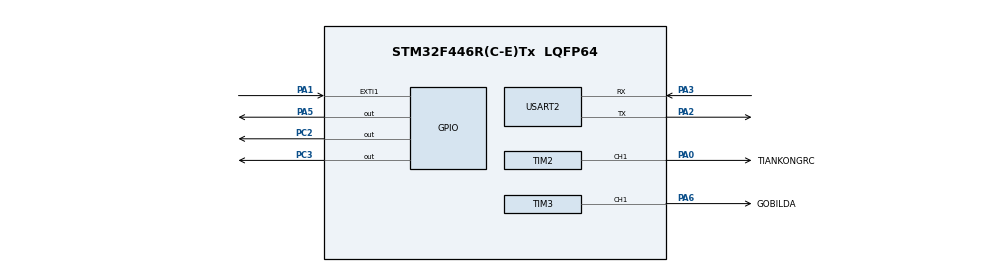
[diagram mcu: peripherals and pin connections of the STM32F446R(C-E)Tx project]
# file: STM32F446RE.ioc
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Dma.Request0=USART2_RX
Dma.Request1=USART2_TX
Dma.USART2_RX.0.Direction=DMA_PERIPH_TO_MEMORY
Dma.USART2_RX.0.FIFOMode=DMA_FIFOMODE_DISABLE
Dma.USART2_RX.0.Instance=DMA1_Stream5
Dma.USART2_RX.0.MemDataAlignment=DMA_MDATAALIGN_BYTE
Dma.USART2_RX.0.MemInc=DMA_MINC_ENABLE
Dma.USART2_RX.0.Mode=DMA_CIRCULAR
Dma.USART2_RX.0.PeriphDataAlignment=DMA_PDATAALIGN_BYTE
Dma.USART2_RX.0.PeriphInc=DMA_PINC_DISABLE
Dma.USART2_RX.0.Priority=DMA_PRIORITY_VERY_HIGH
Dma.USART2_TX.1.Direction=DMA_MEMORY_TO_PERIPH
Dma.USART2_TX.1.FIFOMode=DMA_FIFOMODE_DISABLE
Dma.USART2_TX.1.Instance=DMA1_Stream6
Dma.USART2_TX.1.MemDataAlignment=DMA_MDATAALIGN_BYTE
Dma.USART2_TX.1.MemInc=DMA_MINC_ENABLE
Dma.USART2_TX.1.Mode=DMA_NORMAL
Dma.USART2_TX.1.PeriphDataAlignment=DMA_PDATAALIGN_BYTE
Dma.USART2_TX.1.PeriphInc=DMA_PINC_DISABLE
Dma.USART2_TX.1.Priority=DMA_PRIORITY_VERY_HIGH
FREERTOS.Tasks01=defaultTask,24,5000,StartDefaultTask,As weak,NULL,Static,defaultTaskBuffer,defaultTaskControlBlock;myTask02,8,2000,StartServoTask,As weak,NULL,Static,myTask02Buffer,myTask02ControlBlock
FREERTOS.configUSE_NEWLIB_REENTRANT=1
Mcu.Family=STM32F4
Mcu.Name=STM32F446R(C-E)Tx
Mcu.Package=LQFP64
NVIC.DMA1_Stream5_IRQn=true\:5\:0\:false\:false\:true\:true\:false\:true\:true
NVIC.DMA1_Stream6_IRQn=true\:5\:0\:false\:false\:true\:true\:false\:true\:true
NVIC.EXTI1_IRQn=true\:5\:0\:false\:false\:true\:true\:true\:true\:true
NVIC.PriorityGroup=NVIC_PRIORITYGROUP_4
NVIC.TIM5_IRQn=true\:5\:0\:false\:false\:true\:true\:true\:true\:true
NVIC.TIM6_DAC_IRQn=true\:15\:0\:false\:false\:true\:false\:false\:true\:true
NVIC.TimeBase=TIM6_DAC_IRQn
NVIC.TimeBaseIP=TIM6
NVIC.USART2_IRQn=true\:5\:0\:false\:false\:true\:true\:true\:true\:true
PA0-WKUP.GPIO_Label=TIANKONGRC
PA0-WKUP.Signal=S_TIM2_CH1_ETR
PA1.GPIO_ModeDefaultEXTI=GPIO_MODE_IT_RISING_FALLING
PA1.GPIO_PuPd=GPIO_PULLUP
PA1.Signal=GPXTI1
PA13.Mode=Serial_Wire
PA13.Signal=SYS_JTMS-SWDIO
PA14.Mode=Serial_Wire
PA14.Signal=SYS_JTCK-SWCLK
PA2.Mode=Asynchronous
PA2.Signal=USART2_TX
PA3.Mode=Asynchronous
PA3.Signal=USART2_RX
PA5.Signal=GPIO_Output
PA6.GPIO_Label=GOBILDA
PA6.Signal=S_TIM3_CH1
PC2.Signal=GPIO_Output
PC3.Signal=GPIO_Output
ProjectManager.HeapSize=0x200
ProjectManager.StackSize=0x400
ProjectManager.TargetToolchain=STM32CubeIDE
RCC.CortexFreq_Value=16000000
RCC.USBFreq_Value=96000000
RCC.VCOOutputFreq_Value=192000000
SH.S_TIM2_CH1_ETR.0=TIM2_CH1,PWM Generation1 CH1
SH.S_TIM3_CH1.0=TIM3_CH1,PWM Generation1 CH1
TIM2.Channel-PWM\ Generation1\ CH1=TIM_CHANNEL_1
TIM3.Channel-PWM\ Generation1\ CH1=TIM_CHANNEL_1
TIM5.Period=10000-1
TIM5.Prescaler=16-1
USART2.VirtualMode=VM_ASYNC
VP_FREERTOS_VS_CMSIS_V2.Mode=CMSIS_V2
VP_SYS_VS_tim6.Mode=TIM6
VP_TIM5_VS_ClockSourceINT.Mode=Internal
board=custom

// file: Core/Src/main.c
/* USER CODE BEGIN Header */
/**
  ******************************************************************************
  * @file           : main.c
  * @brief          : Main program body
  ******************************************************************************
  * @attention
  *
  * Copyright (c) 2026 STMicroelectronics.
  * All rights reserved.
  *
  * This software is licensed under terms that can be found in the LICENSE file
  * in the root directory of this software component.
  * If no LICENSE file comes with this software, it is provided AS-IS.
  *
  ******************************************************************************
  */
/* USER CODE END Header */
#include "main.h"
#include "cmsis_os.h"

typedef StaticTask_t osStaticThreadDef_t;

TIM_HandleTypeDef htim2;
TIM_HandleTypeDef htim3;
TIM_HandleTypeDef htim5;

UART_HandleTypeDef huart2;
DMA_HandleTypeDef hdma_usart2_rx;
DMA_HandleTypeDef hdma_usart2_tx;

/* Definitions for defaultTask */
osThreadId_t defaultTaskHandle;
uint32_t defaultTaskBuffer[ 5000 ];
osStaticThreadDef_t defaultTaskControlBlock;
const osThreadAttr_t defaultTask_attributes = {
  .name = "defaultTask",
  .cb_mem = &defaultTaskControlBlock,
  .cb_size = sizeof(defaultTaskControlBlock),
  .stack_mem = &defaultTaskBuffer[0],
  .stack_size = sizeof(defaultTaskBuffer),
  .priority = (osPriority_t) osPriorityNormal,
};
/* Definitions for myTask02 */
osThreadId_t myTask02Handle;
uint32_t myTask02Buffer[ 2000 ];
osStaticThreadDef_t myTask02ControlBlock;
const osThreadAttr_t myTask02_attributes = {
  .name = "myTask02",
  .cb_mem = &myTask02ControlBlock,
  .cb_size = sizeof(myTask02ControlBlock),
  .stack_mem = &myTask02Buffer[0],
  .stack_size = sizeof(myTask02Buffer),
  .priority = (osPriority_t) osPriorityLow,
};
/* USER CODE BEGIN PV */
int sec =0;
/* USER CODE END PV */

void SystemClock_Config(void);
static void MX_GPIO_Init(void);
static void MX_DMA_Init(void);
static void MX_USART2_UART_Init(void);
static void MX_TIM5_Init(void);
static void MX_TIM2_Init(void);
static void MX_TIM3_Init(void);
void StartDefaultTask(void *argument);
void StartServoTask(void *argument);

int main(void)
{

  /* MCU Configuration--------------------------------------------------------*/

  /* Reset of all peripherals, Initializes the Flash interface and the Systick. */
  HAL_Init();

  /* Configure the system clock */
  SystemClock_Config();

  /* Initialize all configured peripherals */
  MX_GPIO_Init();
  MX_DMA_Init();
  MX_USART2_UART_Init();
  MX_TIM5_Init();
  MX_TIM2_Init();
  MX_TIM3_Init();

  /* Init scheduler */
  osKernelInitialize();

  /* Create the thread(s) */
  /* creation of defaultTask */
  defaultTaskHandle = osThreadNew(StartDefaultTask, NULL, &defaultTask_attributes);

  /* creation of myTask02 */
  myTask02Handle = osThreadNew(StartServoTask, NULL, &myTask02_attributes);

  /* Start scheduler */
  osKernelStart();

  /* We should never get here as control is now taken by the scheduler */

  /* Infinite loop */
  while (1)
  {

  }
}

void SystemClock_Config(void)
{
  RCC_OscInitTypeDef RCC_OscInitStruct = {0};
  RCC_ClkInitTypeDef RCC_ClkInitStruct = {0};

  /** Configure the main internal regulator output voltage
  */
  __HAL_RCC_PWR_CLK_ENABLE();
  __HAL_PWR_VOLTAGESCALING_CONFIG(PWR_REGULATOR_VOLTAGE_SCALE3);

  /** Initializes the RCC Oscillators according to the specified parameters
  * in the RCC_OscInitTypeDef structure.
  */
  RCC_OscInitStruct.OscillatorType = RCC_OSCILLATORTYPE_HSI;
  RCC_OscInitStruct.HSIState = RCC_HSI_ON;
  RCC_OscInitStruct.HSICalibrationValue = RCC_HSICALIBRATION_DEFAULT;
  RCC_OscInitStruct.PLL.PLLState = RCC_PLL_NONE;
  if (HAL_RCC_OscConfig(&RCC_OscInitStruct) != HAL_OK)
  {
    Error_Handler();
  }

  /** Initializes the CPU, AHB and APB buses clocks
  */
  RCC_ClkInitStruct.ClockType = RCC_CLOCKTYPE_HCLK|RCC_CLOCKTYPE_SYSCLK
                              |RCC_CLOCKTYPE_PCLK1|RCC_CLOCKTYPE_PCLK2;
  RCC_ClkInitStruct.SYSCLKSource = RCC_SYSCLKSOURCE_HSI;
  RCC_ClkInitStruct.AHBCLKDivider = RCC_SYSCLK_DIV1;
  RCC_ClkInitStruct.APB1CLKDivider = RCC_HCLK_DIV1;
  RCC_ClkInitStruct.APB2CLKDivider = RCC_HCLK_DIV1;

  if (HAL_RCC_ClockConfig(&RCC_ClkInitStruct, FLASH_LATENCY_0) != HAL_OK)
  {
    Error_Handler();
  }
}

static void MX_TIM2_Init(void)
{

  TIM_MasterConfigTypeDef sMasterConfig = {0};
  TIM_OC_InitTypeDef sConfigOC = {0};

  htim2.Instance = TIM2;
  htim2.Init.Prescaler = 0;
  htim2.Init.CounterMode = TIM_COUNTERMODE_UP;
  htim2.Init.Period = 4294967295;
  htim2.Init.ClockDivision = TIM_CLOCKDIVISION_DIV1;
  htim2.Init.AutoReloadPreload = TIM_AUTORELOAD_PRELOAD_DISABLE;
  if (HAL_TIM_PWM_Init(&htim2) != HAL_OK)
  {
    Error_Handler();
  }
  sMasterConfig.MasterOutputTrigger = TIM_TRGO_RESET;
  sMasterConfig.MasterSlaveMode = TIM_MASTERSLAVEMODE_DISABLE;
  if (HAL_TIMEx_MasterConfigSynchronization(&htim2, &sMasterConfig) != HAL_OK)
  {
    Error_Handler();
  }
  sConfigOC.OCMode = TIM_OCMODE_PWM1;
  sConfigOC.Pulse = 0;
  sConfigOC.OCPolarity = TIM_OCPOLARITY_HIGH;
  sConfigOC.OCFastMode = TIM_OCFAST_DISABLE;
  if (HAL_TIM_PWM_ConfigChannel(&htim2, &sConfigOC, TIM_CHANNEL_1) != HAL_OK)
  {
    Error_Handler();
  }
  HAL_TIM_MspPostInit(&htim2);

}

static void MX_TIM3_Init(void)
{

  TIM_MasterConfigTypeDef sMasterConfig = {0};
  TIM_OC_InitTypeDef sConfigOC = {0};

  htim3.Instance = TIM3;
  htim3.Init.Prescaler = 0;
  htim3.Init.CounterMode = TIM_COUNTERMODE_UP;
  htim3.Init.Period = 65535;
  htim3.Init.ClockDivision = TIM_CLOCKDIVISION_DIV1;
  htim3.Init.AutoReloadPreload = TIM_AUTORELOAD_PRELOAD_DISABLE;
  if (HAL_TIM_PWM_Init(&htim3) != HAL_OK)
  {
    Error_Handler();
  }
  sMasterConfig.MasterOutputTrigger = TIM_TRGO_RESET;
  sMasterConfig.MasterSlaveMode = TIM_MASTERSLAVEMODE_DISABLE;
  if (HAL_TIMEx_MasterConfigSynchronization(&htim3, &sMasterConfig) != HAL_OK)
  {
    Error_Handler();
  }
  sConfigOC.OCMode = TIM_OCMODE_PWM1;
  sConfigOC.Pulse = 0;
  sConfigOC.OCPolarity = TIM_OCPOLARITY_HIGH;
  sConfigOC.OCFastMode = TIM_OCFAST_DISABLE;
  if (HAL_TIM_PWM_ConfigChannel(&htim3, &sConfigOC, TIM_CHANNEL_1) != HAL_OK)
  {
    Error_Handler();
  }
  HAL_TIM_MspPostInit(&htim3);

}

static void MX_TIM5_Init(void)
{

  TIM_ClockConfigTypeDef sClockSourceConfig = {0};
  TIM_MasterConfigTypeDef sMasterConfig = {0};

  htim5.Instance = TIM5;
  htim5.Init.Prescaler = 16-1;
  htim5.Init.CounterMode = TIM_COUNTERMODE_UP;
  htim5.Init.Period = 10000-1;
  htim5.Init.ClockDivision = TIM_CLOCKDIVISION_DIV1;
  htim5.Init.AutoReloadPreload = TIM_AUTORELOAD_PRELOAD_DISABLE;
  if (HAL_TIM_Base_Init(&htim5) != HAL_OK)
  {
    Error_Handler();
  }
  sClockSourceConfig.ClockSource = TIM_CLOCKSOURCE_INTERNAL;
  if (HAL_TIM_ConfigClockSource(&htim5, &sClockSourceConfig) != HAL_OK)
  {
    Error_Handler();
  }
  sMasterConfig.MasterOutputTrigger = TIM_TRGO_RESET;
  sMasterConfig.MasterSlaveMode = TIM_MASTERSLAVEMODE_DISABLE;
  if (HAL_TIMEx_MasterConfigSynchronization(&htim5, &sMasterConfig) != HAL_OK)
  {
    Error_Handler();
  }

}

static void MX_USART2_UART_Init(void)
{

  huart2.Instance = USART2;
  huart2.Init.BaudRate = 115200;
  huart2.Init.WordLength = UART_WORDLENGTH_8B;
  huart2.Init.StopBits = UART_STOPBITS_1;
  huart2.Init.Parity = UART_PARITY_NONE;
  huart2.Init.Mode = UART_MODE_TX_RX;
  huart2.Init.HwFlowCtl = UART_HWCONTROL_NONE;
  huart2.Init.OverSampling = UART_OVERSAMPLING_16;
  if (HAL_UART_Init(&huart2) != HAL_OK)
  {
    Error_Handler();
  }

}

static void MX_DMA_Init(void)
{

  /* DMA controller clock enable */
  __HAL_RCC_DMA1_CLK_ENABLE();

  /* DMA interrupt init */
  /* DMA1_Stream5_IRQn interrupt configuration */
  HAL_NVIC_SetPriority(DMA1_Stream5_IRQn, 5, 0);
  HAL_NVIC_EnableIRQ(DMA1_Stream5_IRQn);
  /* DMA1_Stream6_IRQn interrupt configuration */
  HAL_NVIC_SetPriority(DMA1_Stream6_IRQn, 5, 0);
  HAL_NVIC_EnableIRQ(DMA1_Stream6_IRQn);

}

static void MX_GPIO_Init(void)
{
  GPIO_InitTypeDef GPIO_InitStruct = {0};

  /* GPIO Ports Clock Enable */
  __HAL_RCC_GPIOC_CLK_ENABLE();
  __HAL_RCC_GPIOA_CLK_ENABLE();

  /*Configure GPIO pin Output Level */
  HAL_GPIO_WritePin(GPIOC, GPIO_PIN_2|GPIO_PIN_3, GPIO_PIN_RESET);

  /*Configure GPIO pin Output Level */
  HAL_GPIO_WritePin(GPIOA, GPIO_PIN_5, GPIO_PIN_RESET);

  /*Configure GPIO pins : PC2 PC3 */
  GPIO_InitStruct.Pin = GPIO_PIN_2|GPIO_PIN_3;
  GPIO_InitStruct.Mode = GPIO_MODE_OUTPUT_PP;
  GPIO_InitStruct.Pull = GPIO_NOPULL;
  GPIO_InitStruct.Speed = GPIO_SPEED_FREQ_LOW;
  HAL_GPIO_Init(GPIOC, &GPIO_InitStruct);

  /*Configure GPIO pin : PA1 */
  GPIO_InitStruct.Pin = GPIO_PIN_1;
  GPIO_InitStruct.Mode = GPIO_MODE_IT_RISING_FALLING;
  GPIO_InitStruct.Pull = GPIO_PULLUP;
  HAL_GPIO_Init(GPIOA, &GPIO_InitStruct);

  /*Configure GPIO pin : PA5 */
  GPIO_InitStruct.Pin = GPIO_PIN_5;
  GPIO_InitStruct.Mode = GPIO_MODE_OUTPUT_PP;
  GPIO_InitStruct.Pull = GPIO_NOPULL;
  GPIO_InitStruct.Speed = GPIO_SPEED_FREQ_LOW;
  HAL_GPIO_Init(GPIOA, &GPIO_InitStruct);

  /* EXTI interrupt init*/
  HAL_NVIC_SetPriority(EXTI1_IRQn, 5, 0);
  HAL_NVIC_EnableIRQ(EXTI1_IRQn);

}

__weak void StartDefaultTask(void *argument)
{
  for(;;)
  {
    osDelay(1);
  }
}

__weak void StartServoTask(void *argument)
{
  for(;;)
  {
    osDelay(1);
  }
}

void HAL_TIM_PeriodElapsedCallback(TIM_HandleTypeDef *htim)
{
  /* USER CODE BEGIN Callback 0 */
  if (htim->Instance == TIM5)
  {
	  sec++;
  }
  /* USER CODE END Callback 0 */
  if (htim->Instance == TIM6)
  {
    HAL_IncTick();
  }
}

void Error_Handler(void)
{
  __disable_irq();
  while (1)
  {
  }
}
